# STM32F407_MINI register map
File version: 1.0
Minimal STM32F4 excerpt (RCC, GPIOA, USART2) for Embeder P2 grounding.
Registers are access not given, no defined reset value unless marked. A register's access mark holds for its fields unless they carry their own. Offsets are from the block's base; lines under a group give offsets from that group; [hi:lo] are bit positions; {n}, {i} and the like mark numbered series; 'fields as' and 'values as' point back to an identical list; <NAME> marks a mode.

## Memory map
0x40004400 USART2 — Universal synchronous asynchronous receiver transmitter
0x40020000 GPIOA — General-purpose I/Os port A
0x40023800 RCC — Reset and clock control

## RCC — Reset and clock control
Base 0x40023800
0x30 AHB1ENR — AHB1 peripheral clock enable register
  [0] GPIOAEN — IO port A clock enable
0x40 APB1ENR — APB1 peripheral clock enable register
  [17] USART2EN — USART2 clock enable

## GPIOA — General-purpose I/Os port A
Base 0x40020000
0x00 MODER — GPIO port mode register
0x14 ODR — GPIO port output data register
0x20 AFRL — GPIO alternate function low register

## USART2 — Universal synchronous asynchronous receiver transmitter
Base 0x40004400
0x00 SR — Status register
  [7] TXE — Transmit data register empty
0x04 DR — Data register
0x08 BRR — Baud rate register
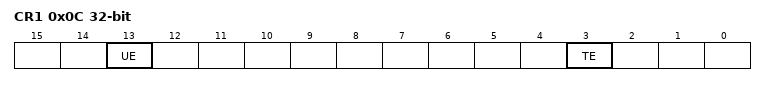
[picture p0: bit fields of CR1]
0x0C CR1 — Control register 1
  [13] UE — USART enable
  [3] TE — Transmitter enable
